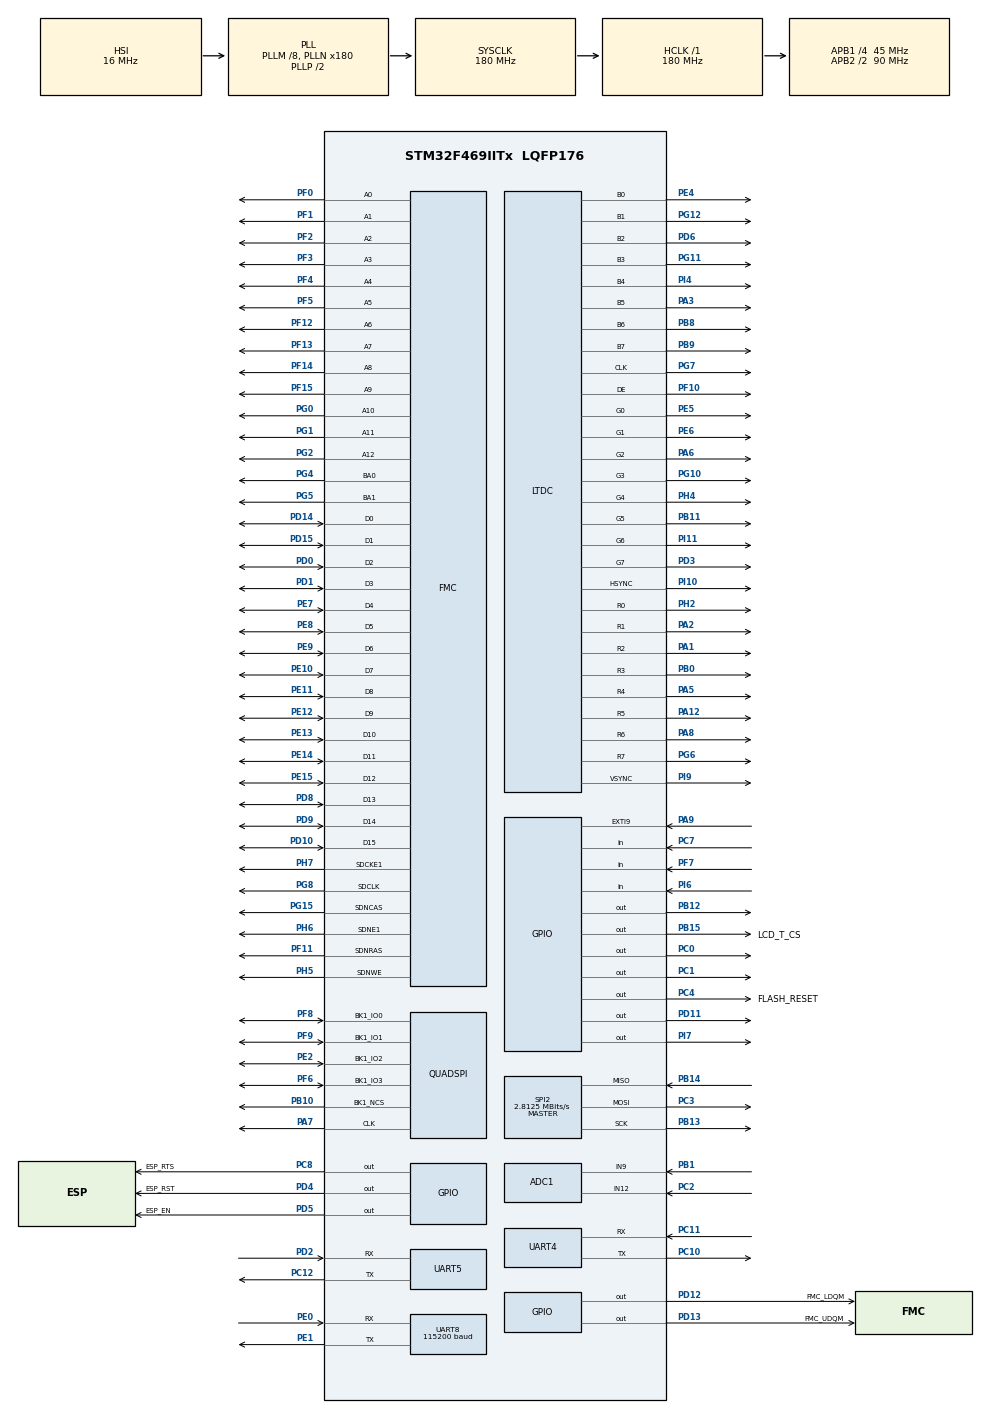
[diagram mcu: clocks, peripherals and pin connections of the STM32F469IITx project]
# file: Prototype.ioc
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ADC1.Channel-1\#ChannelRegularConversion=ADC_CHANNEL_VREFINT
ADC1.ContinuousConvMode=ENABLE
ADC1.DiscontinuousConvMode=DISABLE
ADC1.EnableAnalogWatchDog=false
ADC1.ExternalTrigConv=ADC_SOFTWARE_START
ADC1.InjNumberOfConversion=0
ADC1.NbrOfConversion=1
ADC1.NbrOfConversionFlag=1
ADC1.Rank-1\#ChannelRegularConversion=1
ADC1.SamplingTime-1\#ChannelRegularConversion=ADC_SAMPLETIME_480CYCLES
ADC1.ScanConvMode=ENABLE
ADC1.master=1
DMA2D.ColorMode=DMA2D_OUTPUT_RGB888
Dma.ADC1.0.Direction=DMA_PERIPH_TO_MEMORY
Dma.ADC1.0.FIFOMode=DMA_FIFOMODE_DISABLE
Dma.ADC1.0.Instance=DMA2_Stream0
Dma.ADC1.0.MemDataAlignment=DMA_MDATAALIGN_HALFWORD
Dma.ADC1.0.MemInc=DMA_MINC_ENABLE
Dma.ADC1.0.Mode=DMA_CIRCULAR
Dma.ADC1.0.PeriphDataAlignment=DMA_PDATAALIGN_HALFWORD
Dma.ADC1.0.PeriphInc=DMA_PINC_DISABLE
Dma.ADC1.0.Priority=DMA_PRIORITY_LOW
Dma.Request0=ADC1
FMC.CASLatency1=FMC_SDRAM_CAS_LATENCY_2
FMC.ExitSelfRefreshDelay1=7
FMC.LoadToActiveDelay1=2
FMC.RCDDelay1=3
FMC.RPDelay1=2
FMC.RPDelay2=2
FMC.RowCycleDelay1=6
FMC.RowCycleDelay2=6
FMC.SDClockPeriod1=FMC_SDRAM_CLOCK_PERIOD_2
FMC.SelfRefreshTime1=6
FMC.WriteRecoveryTime1=3
FREERTOS.Tasks01=defaultTask,24,4096,StartDefaultTask,Default,NULL,Dynamic,NULL,NULL
FREERTOS.configTOTAL_HEAP_SIZE=30000
FREERTOS.configUSE_NEWLIB_REENTRANT=1
LTDC.ActiveW=800
LTDC.Alpha0_L0=0
LTDC.Alpha0_L1=0
LTDC.Alpha_L0=255
LTDC.BlendingFactor1_L0=LTDC_BLENDING_FACTOR1_PAxCA
LTDC.BlendingFactor1_L1=LTDC_BLENDING_FACTOR1_PAxCA
LTDC.BlendingFactor2_L0=LTDC_BLENDING_FACTOR2_PAxCA
LTDC.BlendingFactor2_L1=LTDC_BLENDING_FACTOR2_PAxCA
LTDC.Blue_L0=0
LTDC.Blue_L1=255
LTDC.Green=0
LTDC.Green_L0=0
LTDC.Green_L1=255
LTDC.HBP=46
LTDC.HFP=210
LTDC.HSync=41
LTDC.ImageHeight_L0=480
LTDC.ImageWidth_L0=800
LTDC.ImageWidth_L1=800
LTDC.Layers=0
LTDC.PixelFormat_L0=LTDC_PIXEL_FORMAT_RGB888
LTDC.PixelFormat_L1=LTDC_PIXEL_FORMAT_RGB565
LTDC.Red=0
LTDC.Red_L0=0
LTDC.Red_L1=255
LTDC.VBP=23
LTDC.VFP=22
LTDC.VSync=20
LTDC.WindowX1_L0=800
LTDC.WindowX1_L1=800
LTDC.WindowY1_L0=480
LTDC.WindowY1_L1=480
Mcu.Family=STM32F4
Mcu.Name=STM32F469IITx
Mcu.Package=LQFP176
NVIC.DMA2D_IRQn=true\:5\:0\:false\:false\:true\:true\:true\:true\:true
NVIC.DMA2_Stream0_IRQn=true\:5\:0\:false\:false\:true\:true\:false\:true\:true
NVIC.LTDC_IRQn=true\:5\:0\:true\:false\:true\:true\:true\:true\:true
NVIC.PriorityGroup=NVIC_PRIORITYGROUP_4
NVIC.TIM6_DAC_IRQn=true\:15\:0\:true\:false\:true\:false\:false\:true\:true
NVIC.TimeBase=TIM6_DAC_IRQn
NVIC.TimeBaseIP=TIM6
PA0/WKUP.Mode=SYS_WakeUp0
PA0/WKUP.Signal=SYS_WKUP
PA1.Mode=RGB888
PA1.Signal=LTDC_R2
PA12.Mode=RGB888
PA12.Signal=LTDC_R5
PA13.Mode=JTAG_5_pins
PA13.Signal=SYS_JTMS-SWDIO
PA14.Mode=JTAG_5_pins
PA14.Signal=SYS_JTCK-SWCLK
PA15.Mode=JTAG_5_pins
PA15.Signal=SYS_JTDI
PA2.Mode=RGB888
PA2.Signal=LTDC_R1
PA3.Mode=RGB888
PA3.Signal=LTDC_B5
PA5.Mode=RGB888
PA5.Signal=LTDC_R4
PA6.Mode=RGB888
PA6.Signal=LTDC_G2
PA7.Mode=Single Bank 1
PA7.Signal=QUADSPI_CLK
PA8.Mode=RGB888
PA8.Signal=LTDC_R6
PA9.GPIO_ModeDefaultEXTI=GPIO_MODE_IT_FALLING
PA9.GPIO_PuPd=GPIO_PULLUP
PA9.Signal=GPXTI9
PB0.Mode=RGB888
PB0.Signal=LTDC_R3
PB1.Signal=ADCx_IN9
PB10.Mode=Single Bank 1
PB10.Signal=QUADSPI_BK1_NCS
PB11.Mode=RGB888
PB11.Signal=LTDC_G5
PB12.Signal=GPIO_Output
PB13.Mode=Full_Duplex_Master
PB13.Signal=SPI2_SCK
PB14.Mode=Full_Duplex_Master
PB14.Signal=SPI2_MISO
PB15.GPIO_Label=LCD_T_CS
PB15.Signal=GPIO_Output
PB3.Mode=JTAG_5_pins
PB3.Signal=SYS_JTDO-SWO
PB4.Mode=JTAG_5_pins
PB4.Signal=SYS_JTRST
PB8.Mode=RGB888
PB8.Signal=LTDC_B6
PB9.Mode=RGB888
PB9.Signal=LTDC_B7
PC0.Signal=GPIO_Output
PC1.Signal=GPIO_Output
PC10.Mode=Asynchronous
PC10.Signal=UART4_TX
PC11.Mode=Asynchronous
PC11.Signal=UART4_RX
PC12.Mode=Asynchronous
PC12.Signal=UART5_TX
PC2.Signal=ADCx_IN12
PC3.Mode=Full_Duplex_Master
PC3.Signal=SPI2_MOSI
PC4.GPIO_Label=FLASH_RESET
PC4.Signal=GPIO_Output
PC7.Signal=GPIO_Input
PC8.GPIO_Label=ESP_RTS
PC8.Signal=GPIO_Output
PD0.Signal=FMC_D2_DA2
PD1.Signal=FMC_D3_DA3
PD10.Signal=FMC_D15_DA15
PD11.Signal=GPIO_Output
PD12.GPIO_Label=FMC_LDQM
PD12.Signal=GPIO_Output
PD13.GPIO_Label=FMC_UDQM
PD13.Signal=GPIO_Output
PD14.Signal=FMC_D0_DA0
PD15.Signal=FMC_D1_DA1
PD2.Mode=Asynchronous
PD2.Signal=UART5_RX
PD3.Mode=RGB888
PD3.Signal=LTDC_G7
PD4.GPIO_Label=ESP_RST
PD4.Signal=GPIO_Output
PD5.GPIO_Label=ESP_EN
PD5.GPIO_ModeDefaultOutputPP=GPIO_MODE_OUTPUT_OD
PD5.GPIO_PuPd=GPIO_PULLUP
PD5.Signal=GPIO_Output
PD6.Mode=RGB888
PD6.Signal=LTDC_B2
PD8.Signal=FMC_D13_DA13
PD9.Signal=FMC_D14_DA14
PE0.Mode=Asynchronous
PE0.Signal=UART8_RX
PE1.Mode=Asynchronous
PE1.Signal=UART8_TX
PE10.Signal=FMC_D7_DA7
PE11.Signal=FMC_D8_DA8
PE12.Signal=FMC_D9_DA9
PE13.Signal=FMC_D10_DA10
PE14.Signal=FMC_D11_DA11
PE15.Signal=FMC_D12_DA12
PE2.Mode=Single Bank 1
PE2.Signal=QUADSPI_BK1_IO2
PE4.Mode=RGB888
PE4.Signal=LTDC_B0
PE5.Mode=RGB888
PE5.Signal=LTDC_G0
PE6.Mode=RGB888
PE6.Signal=LTDC_G1
PE7.Signal=FMC_D4_DA4
PE8.Signal=FMC_D5_DA5
PE9.Signal=FMC_D6_DA6
PF0.Signal=FMC_A0
PF1.Signal=FMC_A1
PF10.Mode=RGB888
PF10.Signal=LTDC_DE
PF11.Signal=FMC_SDNRAS
PF12.Signal=FMC_A6
PF13.Signal=FMC_A7
PF14.Signal=FMC_A8
PF15.Signal=FMC_A9
PF2.Signal=FMC_A2
PF3.Signal=FMC_A3
PF4.Signal=FMC_A4
PF5.Signal=FMC_A5
PF6.Mode=Single Bank 1
PF6.Signal=QUADSPI_BK1_IO3
PF7.Signal=GPIO_Input
PF8.Mode=Single Bank 1
PF8.Signal=QUADSPI_BK1_IO0
PF9.Mode=Single Bank 1
PF9.Signal=QUADSPI_BK1_IO1
PG0.Signal=FMC_A10
PG1.Signal=FMC_A11
PG10.Mode=RGB888
PG10.Signal=LTDC_G3
PG11.Mode=RGB888
PG11.Signal=LTDC_B3
PG12.Mode=RGB888
PG12.Signal=LTDC_B1
PG15.Signal=FMC_SDNCAS
PG2.Signal=FMC_A12
PG4.Signal=FMC_A14_BA0
PG5.Signal=FMC_A15_BA1
PG6.Mode=RGB888
PG6.Signal=LTDC_R7
PG7.Mode=RGB888
PG7.Signal=LTDC_CLK
PG8.Signal=FMC_SDCLK
PH2.Mode=RGB888
PH2.Signal=LTDC_R0
PH4.Mode=RGB888
PH4.Signal=LTDC_G4
PH5.Signal=FMC_SDNWE
PH6.Mode=SdramChipSelect2_1
PH6.Signal=FMC_SDNE1
PH7.Mode=SdramChipSelect2_1
PH7.Signal=FMC_SDCKE1
PI10.Mode=RGB888
PI10.Signal=LTDC_HSYNC
PI11.Mode=RGB888
PI11.Signal=LTDC_G6
PI4.Mode=RGB888
PI4.Signal=LTDC_B4
PI6.Signal=GPIO_Input
PI7.Signal=GPIO_Output
PI9.Mode=RGB888
PI9.Signal=LTDC_VSYNC
ProjectManager.HeapSize=0x200
ProjectManager.StackSize=0x400
ProjectManager.TargetToolchain=STM32CubeIDE
RCC.AHBFreq_Value=180000000
RCC.APB1CLKDivider=RCC_HCLK_DIV4
RCC.APB1Freq_Value=45000000
RCC.APB1TimFreq_Value=90000000
RCC.APB2CLKDivider=RCC_HCLK_DIV2
RCC.APB2Freq_Value=90000000
RCC.APB2TimFreq_Value=180000000
RCC.CortexFreq_Value=180000000
RCC.HCLKFreq_Value=180000000
RCC.HSE_VALUE=25000000
RCC.PLLM=8
RCC.PLLN=180
RCC.PLLSAIN=50
RCC.SYSCLKFreq_VALUE=180000000
RCC.SYSCLKSource=RCC_SYSCLKSOURCE_PLLCLK
RCC.USBFreq_Value=90000000
RCC.VCOOutputFreq_Value=360000000
SH.ADCx_IN12.0=ADC1_IN12,IN12
SH.ADCx_IN9.0=ADC1_IN9,IN9
SH.FMC_A0.0=FMC_A0,13b-sda1
SH.FMC_A1.0=FMC_A1,13b-sda1
SH.FMC_A10.0=FMC_A10,13b-sda1
SH.FMC_A11.0=FMC_A11,13b-sda1
SH.FMC_A12.0=FMC_A12,13b-sda1
SH.FMC_A14_BA0.0=FMC_BA0,FourSdramBanks1
SH.FMC_A15_BA1.0=FMC_BA1,FourSdramBanks1
SH.FMC_A2.0=FMC_A2,13b-sda1
SH.FMC_A3.0=FMC_A3,13b-sda1
SH.FMC_A4.0=FMC_A4,13b-sda1
SH.FMC_A5.0=FMC_A5,13b-sda1
SH.FMC_A6.0=FMC_A6,13b-sda1
SH.FMC_A7.0=FMC_A7,13b-sda1
SH.FMC_A8.0=FMC_A8,13b-sda1
SH.FMC_A9.0=FMC_A9,13b-sda1
SH.FMC_D0_DA0.0=FMC_D0,sd-16b-d1
SH.FMC_D10_DA10.0=FMC_D10,sd-16b-d1
SH.FMC_D11_DA11.0=FMC_D11,sd-16b-d1
SH.FMC_D12_DA12.0=FMC_D12,sd-16b-d1
SH.FMC_D13_DA13.0=FMC_D13,sd-16b-d1
SH.FMC_D14_DA14.0=FMC_D14,sd-16b-d1
SH.FMC_D15_DA15.0=FMC_D15,sd-16b-d1
SH.FMC_D1_DA1.0=FMC_D1,sd-16b-d1
SH.FMC_D2_DA2.0=FMC_D2,sd-16b-d1
SH.FMC_D3_DA3.0=FMC_D3,sd-16b-d1
SH.FMC_D4_DA4.0=FMC_D4,sd-16b-d1
SH.FMC_D5_DA5.0=FMC_D5,sd-16b-d1
SH.FMC_D6_DA6.0=FMC_D6,sd-16b-d1
SH.FMC_D7_DA7.0=FMC_D7,sd-16b-d1
SH.FMC_D8_DA8.0=FMC_D8,sd-16b-d1
SH.FMC_D9_DA9.0=FMC_D9,sd-16b-d1
SH.FMC_SDCLK.0=FMC_SDCLK,13b-sda1
SH.FMC_SDNCAS.0=FMC_SDNCAS,13b-sda1
SH.FMC_SDNRAS.0=FMC_SDNRAS,13b-sda1
SH.FMC_SDNWE.0=FMC_SDNWE,13b-sda1
SPI2.BaudRatePrescaler=SPI_BAUDRATEPRESCALER_16
SPI2.CalculateBaudRate=2.8125 MBits/s
SPI2.Direction=SPI_DIRECTION_2LINES
SPI2.Mode=SPI_MODE_MASTER
SPI2.VirtualType=VM_MASTER
STMicroelectronics.X-CUBE-TOUCHGFX.4.25.0.ApplicationCcGraphicsJjApplication=TouchGFXOoGenerator
STMicroelectronics.X-CUBE-TOUCHGFX.4.25.0.tgfx_address1=0xD0000000
STMicroelectronics.X-CUBE-TOUCHGFX.4.25.0.tgfx_custom_height=480
STMicroelectronics.X-CUBE-TOUCHGFX.4.25.0.tgfx_datareader_mem_base_address=0xD0000000
STMicroelectronics.X-CUBE-TOUCHGFX.4.25.0.tgfx_display_interface=disp_ltdc
STMicroelectronics.X-CUBE-TOUCHGFX.4.25.0.tgfx_framebuffer_stride=Disabled
STMicroelectronics.X-CUBE-TOUCHGFX.4.25.0.tgfx_hardware_accelerator=dma_2d
STMicroelectronics.X-CUBE-TOUCHGFX.4.25.0.tgfx_location=By Address
STMicroelectronics.X-CUBE-TOUCHGFX.4.25.0.tgfx_vsync=vsync_ltdc
STMicroelectronics.X-CUBE-TOUCHGFX.4.25.0_IsPackSelfContextualization=true
UART4.VirtualMode=Asynchronous
UART5.VirtualMode=Asynchronous
UART8.BaudRate=115200
UART8.VirtualMode=Asynchronous
VP_ADC1_Vref_Input.Mode=IN-Vrefint
VP_CRC_VS_CRC.Mode=CRC_Activate
VP_DMA2D_VS_DMA2D.Mode=DMA2D_Activate
VP_FREERTOS_VS_CMSIS_V2.Mode=CMSIS_V2
VP_STMicroelectronics.X-CUBE-TOUCHGFX_VS_GraphicsJjApplication_4.25.0.Mode=GraphicsJjApplication
VP_SYS_VS_tim6.Mode=TIM6
board=custom

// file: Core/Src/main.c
/* USER CODE BEGIN Header */
/**
  ******************************************************************************
  * @file           : main.c
  * @brief          : Main program body
  ******************************************************************************
  * @attention
  *
  * Copyright (c) 2025 STMicroelectronics.
  * All rights reserved.
  *
  * This software is licensed under terms that can be found in the LICENSE file
  * in the root directory of this software component.
  * If no LICENSE file comes with this software, it is provided AS-IS.
  *
  ******************************************************************************
  */
/* USER CODE END Header */
#include "main.h"
#include "cmsis_os.h"
#include "app_touchgfx.h"

/* USER CODE BEGIN Includes */
#include<stdlib.h>
#include<stdio.h>
#include<string.h>
#include<stdbool.h>
#include <stdint.h>
#include <serial_printing.h>
#include "GUI.h"
#include "types.h"
#include "touch.h"
#include "control.h"

// Initialize the framebuffer to a specific color, e.g., 0xFFFF (white in RGB565)

/*static const uint8_t framebuffer[FRAMEBUFFER_SIZE] = {
    [0 ... FRAMEBUFFER_SIZE - 1] = color_index  // GNU C extension to initialize all elements
};*/ /*780 x 400*/
uint32_t adcs[2] = {0};
/* USER CODE END Includes */

/* USER CODE BEGIN PD */
volatile uint8_t uart8_tx_complete = 0;
/* USER CODE END PD */

ADC_HandleTypeDef hadc1;
DMA_HandleTypeDef hdma_adc1;

CRC_HandleTypeDef hcrc;

DMA2D_HandleTypeDef hdma2d;

LTDC_HandleTypeDef hltdc;

QSPI_HandleTypeDef hqspi;

SPI_HandleTypeDef hspi2;

UART_HandleTypeDef huart4;
UART_HandleTypeDef huart5;
UART_HandleTypeDef huart8;

SDRAM_HandleTypeDef hsdram1;

/* Definitions for defaultTask */
osThreadId_t defaultTaskHandle;
const osThreadAttr_t defaultTask_attributes = {
  .name = "defaultTask",
  .stack_size = 4096 * 4,
  .priority = (osPriority_t) osPriorityNormal,
};
/* USER CODE BEGIN PV */
__IO uint16_t uhADCxConvertedValue = 0;
uint8_t         ubAnalogWatchdogStatus = RESET;

ADC_ChannelConfTypeDef sConfig = {0};
GPIO_InitTypeDef GPIO_InitStruct = {0};

/* USER CODE END PV */

void SystemClock_Config(void);
static void MX_GPIO_Init(void);
static void MX_DMA_Init(void);
static void MX_LTDC_Init(void);
static void MX_FMC_Init(void);
static void MX_ADC1_Init(void);
static void MX_QUADSPI_Init(void);
static void MX_SPI2_Init(void);
static void MX_UART4_Init(void);
static void MX_UART8_Init(void);
static void MX_UART5_Init(void);
static void MX_CRC_Init(void);
static void MX_DMA2D_Init(void);
void StartDefaultTask(void *argument);

/* USER CODE BEGIN PFP */
void RESTORE_ADC();
/* USER CODE END PFP */

/* USER CODE BEGIN 0 */

char rxBuffer[1024];
uint8_t flag = 0x00;
char uartBuffer[1024] = {};
uint16_t *BUFFER_LAYER_1;
uint16_t *BUFFER_LAYER_2;
uint32_t ADC_THREAD_CONTROL_BIT;
uint32_t UART_THREAD_CONTROL_BIT;
uint32_t LCD_THREAD_CONTROL_BIT;

uint32_t MAIN_THREAD_ADC_CONTROL_BIT;
uint32_t MAIN_THREAD_UART_CONTROL_BIT;
uint32_t MAIN_THREAD_LCD_CONTROL_BIT;

DATA_HOLDER mainDataHolder;
DATA_HOLDER lcdDataHolder;

CMD cmd = {
		.origin = {0},
		.protocol = {0},
		.command = {0},
		.args = {0},
		.cmd_all = {0},
		.cmd_all_tmp = {0},
		.cmd_flag = 0x00,
		.status_busy = false
};

Button button = {
		  .c = {0},
		  .data = 25,
		  .n = 0,
		  .rst = false,
		  .set = false,
		  .temp_set = 0,
		  .valid = false,
		  .value = 0
};
Pressed pressed = {
		  .X_ = 0,
		  .Y_=0
};
char msg2[100];
/* USER CODE END 0 */

int main(void)
{

  /* USER CODE BEGIN 1 */
	strcpy(mainDataHolder.callingWaterTemp, "calling");
	strcpy(mainDataHolder.hotWaterTemp, "hot");
	strcpy(mainDataHolder.motor_position, "motor");
	strcpy(mainDataHolder.showerWaterTemp, "shower");

	lcdDataHolder.setTemp = 25;
	//uint16_t *BUFFER_LAYER_1 = (uint16_t *)BUFFER_LAYER_1_ADDRESS;
	//uint16_t *BUFFER_LAYER_2 = (uint16_t *)BUFFER_LAYER_2_ADDRESS;

    //HAL_SDRAM_Write_16b(&hsdram1, (uint32_t *)BUFFER_LAYER_1, (uint16_t *)RGB565_Dark_sky_blue, FRAMEBUFFER_WIDTH * FRAMEBUFFER_HEIGHT);

  /* USER CODE END 1 */

  /* MCU Configuration--------------------------------------------------------*/

  /* Reset of all peripherals, Initializes the Flash interface and the Systick. */
  HAL_Init();

  /* Configure the system clock */
  SystemClock_Config();

  /* Initialize all configured peripherals */
  MX_GPIO_Init();
  MX_DMA_Init();
  MX_LTDC_Init();
  MX_FMC_Init();
  MX_ADC1_Init();
  MX_QUADSPI_Init();
  MX_SPI2_Init();
  MX_UART4_Init();
  MX_UART8_Init();
  MX_UART5_Init();
  MX_CRC_Init();
  MX_DMA2D_Init();
  MX_TouchGFX_Init();
  /* Call PreOsInit function */
  MX_TouchGFX_PreOSInit();
  /* USER CODE BEGIN 2 */

  /* Infinite loop */
	// Allocate buffer

	//  int y_ = 0;

	/*  uint16_t yellow_rgb565 = 0x0f0f;
	  for (int y = 0; y < FRAMEBUFFER_HEIGHT; y++) {
	          for (int x = 0; x < FRAMEBUFFER_WIDTH; x++) {
	        	  uint32_t index = y * FRAMEBUFFER_WIDTH + x; // 1D index
	        	  uint32_t address = (uint32_t)BUFFER_LAYER_1_ADDRESS + index * BYTES_PER_PIXEL; // SDRAM address
	              HAL_SDRAM_Write_16b(&hsdram1, (uint32_t *)address, &yellow_rgb565, 1);
	              address += BYTES_PER_PIXEL; // Increment by 2 bytes for each pixel
	          }
	      }*/
	  HAL_Delay(1000);

	//LCD_Fill(BUFFER_LAYER_1_ADDRESS, 0, 0,FRAMEBUFFER_WIDTH,FRAMEBUFFER_HEIGHT,RGB565_Celtic_blue);
	ESP_RST_GPIO_Port->BSRR = 1U << (4+16);
	ESP_EN_GPIO_Port->BSRR = 1U << (5+16);
	HAL_Delay(1000);
	ESP_RST_GPIO_Port->BSRR = 1U << (4);
	ESP_EN_GPIO_Port->BSRR = 1U << 5;

	//sprintf(msg2, "JUST GOT HERE 7\n");
	//HAL_UART_Transmit(&huart8, (uint8_t *)msg2, strlen(msg2), 1000);

	HAL_Delay(1000);
	ESP_RTS_GPIO_Port->BSRR = 1U << (8+16);
	//ESP_RTS_GPIO_Port->BSRR = 1U << (8);
	GPIOC->BSRR = 1U << 2; // YD
	//char msg1[100] = "RUN 2 200";
//	MX_TouchGFX_Init();
  /* USER CODE END 2 */

  /* Init scheduler */
  osKernelInitialize();

  /* Create the thread(s) */
  /* creation of defaultTask */
  defaultTaskHandle = osThreadNew(StartDefaultTask, NULL, &defaultTask_attributes);

  /* Start scheduler */
  osKernelStart();

  /* We should never get here as control is now taken by the scheduler */

  /* Infinite loop */
  /* USER CODE BEGIN WHILE */
	//memset(adcReadings, 0, sizeof(adcReadings));
    //HAL_ADC_Start_DMA(&hadc1, (uint32_t *)adcReadings, 1000);
  while (1)
  {
    /* USER CODE END WHILE */

    /* USER CODE BEGIN 3 */
	  //HAL_SDRAM_Read_8b(&hsdram1, (uint32_t *)BUFFER_LAYER_1, (uint8_t *)myReadData, 4);
	// Reconfigure ADC to use the correct input channel (e.g., ADC_CHANNEL_9 on PB1
	//printf_(buffer2, myReadData);
  }
  /* USER CODE END 3 */
}

void SystemClock_Config(void)
{
  RCC_OscInitTypeDef RCC_OscInitStruct = {0};
  RCC_ClkInitTypeDef RCC_ClkInitStruct = {0};

  /** Configure the main internal regulator output voltage
  */
  __HAL_RCC_PWR_CLK_ENABLE();
  __HAL_PWR_VOLTAGESCALING_CONFIG(PWR_REGULATOR_VOLTAGE_SCALE1);

  /** Initializes the RCC Oscillators according to the specified parameters
  * in the RCC_OscInitTypeDef structure.
  */
  RCC_OscInitStruct.OscillatorType = RCC_OSCILLATORTYPE_HSI;
  RCC_OscInitStruct.HSIState = RCC_HSI_ON;
  RCC_OscInitStruct.HSICalibrationValue = RCC_HSICALIBRATION_DEFAULT;
  RCC_OscInitStruct.PLL.PLLState = RCC_PLL_ON;
  RCC_OscInitStruct.PLL.PLLSource = RCC_PLLSOURCE_HSI;
  RCC_OscInitStruct.PLL.PLLM = 8;
  RCC_OscInitStruct.PLL.PLLN = 180;
  RCC_OscInitStruct.PLL.PLLP = RCC_PLLP_DIV2;
  RCC_OscInitStruct.PLL.PLLQ = 4;
  RCC_OscInitStruct.PLL.PLLR = 2;
  if (HAL_RCC_OscConfig(&RCC_OscInitStruct) != HAL_OK)
  {
    Error_Handler();
  }

  /** Activate the Over-Drive mode
  */
  if (HAL_PWREx_EnableOverDrive() != HAL_OK)
  {
    Error_Handler();
  }

  /** Initializes the CPU, AHB and APB buses clocks
  */
  RCC_ClkInitStruct.ClockType = RCC_CLOCKTYPE_HCLK|RCC_CLOCKTYPE_SYSCLK
                              |RCC_CLOCKTYPE_PCLK1|RCC_CLOCKTYPE_PCLK2;
  RCC_ClkInitStruct.SYSCLKSource = RCC_SYSCLKSOURCE_PLLCLK;
  RCC_ClkInitStruct.AHBCLKDivider = RCC_SYSCLK_DIV1;
  RCC_ClkInitStruct.APB1CLKDivider = RCC_HCLK_DIV4;
  RCC_ClkInitStruct.APB2CLKDivider = RCC_HCLK_DIV2;

  if (HAL_RCC_ClockConfig(&RCC_ClkInitStruct, FLASH_LATENCY_5) != HAL_OK)
  {
    Error_Handler();
  }
}

static void MX_ADC1_Init(void)
{

  ADC_ChannelConfTypeDef sConfig = {0};

  /** Configure the global features of the ADC (Clock, Resolution, Data Alignment and number of conversion)
  */
  hadc1.Instance = ADC1;
  hadc1.Init.ClockPrescaler = ADC_CLOCK_SYNC_PCLK_DIV4;
  hadc1.Init.Resolution = ADC_RESOLUTION_12B;
  hadc1.Init.ScanConvMode = ENABLE;
  hadc1.Init.ContinuousConvMode = ENABLE;
  hadc1.Init.DiscontinuousConvMode = DISABLE;
  hadc1.Init.ExternalTrigConvEdge = ADC_EXTERNALTRIGCONVEDGE_NONE;
  hadc1.Init.ExternalTrigConv = ADC_SOFTWARE_START;
  hadc1.Init.DataAlign = ADC_DATAALIGN_RIGHT;
  hadc1.Init.NbrOfConversion = 1;
  hadc1.Init.DMAContinuousRequests = DISABLE;
  hadc1.Init.EOCSelection = ADC_EOC_SINGLE_CONV;
  if (HAL_ADC_Init(&hadc1) != HAL_OK)
  {
    Error_Handler();
  }

  /** Configure for the selected ADC regular channel its corresponding rank in the sequencer and its sample time.
  */
  sConfig.Channel = ADC_CHANNEL_VREFINT;
  sConfig.Rank = 1;
  sConfig.SamplingTime = ADC_SAMPLETIME_480CYCLES;
  if (HAL_ADC_ConfigChannel(&hadc1, &sConfig) != HAL_OK)
  {
    Error_Handler();
  }

}

static void MX_CRC_Init(void)
{

  hcrc.Instance = CRC;
  if (HAL_CRC_Init(&hcrc) != HAL_OK)
  {
    Error_Handler();
  }

}

static void MX_DMA2D_Init(void)
{

  hdma2d.Instance = DMA2D;
  hdma2d.Init.Mode = DMA2D_M2M;
  hdma2d.Init.ColorMode = DMA2D_OUTPUT_RGB888;
  hdma2d.Init.OutputOffset = 0;
  hdma2d.LayerCfg[1].InputOffset = 0;
  hdma2d.LayerCfg[1].InputColorMode = DMA2D_INPUT_RGB888;
  hdma2d.LayerCfg[1].AlphaMode = DMA2D_NO_MODIF_ALPHA;
  hdma2d.LayerCfg[1].InputAlpha = 0;
  if (HAL_DMA2D_Init(&hdma2d) != HAL_OK)
  {
    Error_Handler();
  }
  if (HAL_DMA2D_ConfigLayer(&hdma2d, 1) != HAL_OK)
  {
    Error_Handler();
  }

}

static void MX_LTDC_Init(void)
{

  /* USER CODE BEGIN LTDC_Init 0 */
	GPIOB->BSRR = (1U << 12);

  /* USER CODE END LTDC_Init 0 */

  LTDC_LayerCfgTypeDef pLayerCfg = {0};

  hltdc.Instance = LTDC;
  hltdc.Init.HSPolarity = LTDC_HSPOLARITY_AL;
  hltdc.Init.VSPolarity = LTDC_VSPOLARITY_AL;
  hltdc.Init.DEPolarity = LTDC_DEPOLARITY_AL;
  hltdc.Init.PCPolarity = LTDC_PCPOLARITY_IPC;
  hltdc.Init.HorizontalSync = 40;
  hltdc.Init.VerticalSync = 19;
  hltdc.Init.AccumulatedHBP = 86;
  hltdc.Init.AccumulatedVBP = 42;
  hltdc.Init.AccumulatedActiveW = 886;
  hltdc.Init.AccumulatedActiveH = 522;
  hltdc.Init.TotalWidth = 1096;
  hltdc.Init.TotalHeigh = 544;
  hltdc.Init.Backcolor.Blue = 0;
  hltdc.Init.Backcolor.Green = 0;
  hltdc.Init.Backcolor.Red = 0;
  if (HAL_LTDC_Init(&hltdc) != HAL_OK)
  {
    Error_Handler();
  }
  pLayerCfg.WindowX0 = 0;
  pLayerCfg.WindowX1 = 800;
  pLayerCfg.WindowY0 = 0;
  pLayerCfg.WindowY1 = 480;
  pLayerCfg.PixelFormat = LTDC_PIXEL_FORMAT_RGB888;
  pLayerCfg.Alpha = 255;
  pLayerCfg.Alpha0 = 0;
  pLayerCfg.BlendingFactor1 = LTDC_BLENDING_FACTOR1_PAxCA;
  pLayerCfg.BlendingFactor2 = LTDC_BLENDING_FACTOR2_PAxCA;
  pLayerCfg.FBStartAdress = ((uint32_t)0xD0000000);
  pLayerCfg.ImageWidth = 800;
  pLayerCfg.ImageHeight = 480;
  pLayerCfg.Backcolor.Blue = 0;
  pLayerCfg.Backcolor.Green = 0;
  pLayerCfg.Backcolor.Red = 0;
  if (HAL_LTDC_ConfigLayer(&hltdc, &pLayerCfg, 0) != HAL_OK)
  {
    Error_Handler();
  }

}

static void MX_QUADSPI_Init(void)
{

  /* QUADSPI parameter configuration*/
  hqspi.Instance = QUADSPI;
  hqspi.Init.ClockPrescaler = 255;
  hqspi.Init.FifoThreshold = 1;
  hqspi.Init.SampleShifting = QSPI_SAMPLE_SHIFTING_NONE;
  hqspi.Init.FlashSize = 1;
  hqspi.Init.ChipSelectHighTime = QSPI_CS_HIGH_TIME_1_CYCLE;
  hqspi.Init.ClockMode = QSPI_CLOCK_MODE_0;
  hqspi.Init.FlashID = QSPI_FLASH_ID_1;
  hqspi.Init.DualFlash = QSPI_DUALFLASH_DISABLE;
  if (HAL_QSPI_Init(&hqspi) != HAL_OK)
  {
    Error_Handler();
  }

}

static void MX_SPI2_Init(void)
{

  /* SPI2 parameter configuration*/
  hspi2.Instance = SPI2;
  hspi2.Init.Mode = SPI_MODE_MASTER;
  hspi2.Init.Direction = SPI_DIRECTION_2LINES;
  hspi2.Init.DataSize = SPI_DATASIZE_8BIT;
  hspi2.Init.CLKPolarity = SPI_POLARITY_LOW;
  hspi2.Init.CLKPhase = SPI_PHASE_1EDGE;
  hspi2.Init.NSS = SPI_NSS_SOFT;
  hspi2.Init.BaudRatePrescaler = SPI_BAUDRATEPRESCALER_16;
  hspi2.Init.FirstBit = SPI_FIRSTBIT_MSB;
  hspi2.Init.TIMode = SPI_TIMODE_DISABLE;
  hspi2.Init.CRCCalculation = SPI_CRCCALCULATION_DISABLE;
  hspi2.Init.CRCPolynomial = 10;
  if (HAL_SPI_Init(&hspi2) != HAL_OK)
  {
    Error_Handler();
  }

}

static void MX_UART4_Init(void)
{

  huart4.Instance = UART4;
  huart4.Init.BaudRate = 115200;
  huart4.Init.WordLength = UART_WORDLENGTH_8B;
  huart4.Init.StopBits = UART_STOPBITS_1;
  huart4.Init.Parity = UART_PARITY_NONE;
  huart4.Init.Mode = UART_MODE_TX_RX;
  huart4.Init.HwFlowCtl = UART_HWCONTROL_NONE;
  huart4.Init.OverSampling = UART_OVERSAMPLING_16;
  if (HAL_UART_Init(&huart4) != HAL_OK)
  {
    Error_Handler();
  }

}

static void MX_UART5_Init(void)
{

  huart5.Instance = UART5;
  huart5.Init.BaudRate = 115200;
  huart5.Init.WordLength = UART_WORDLENGTH_8B;
  huart5.Init.StopBits = UART_STOPBITS_1;
  huart5.Init.Parity = UART_PARITY_NONE;
  huart5.Init.Mode = UART_MODE_TX_RX;
  huart5.Init.HwFlowCtl = UART_HWCONTROL_NONE;
  huart5.Init.OverSampling = UART_OVERSAMPLING_16;
  if (HAL_UART_Init(&huart5) != HAL_OK)
  {
    Error_Handler();
  }

}

static void MX_UART8_Init(void)
{

  huart8.Instance = UART8;
  huart8.Init.BaudRate = 115200;
  huart8.Init.WordLength = UART_WORDLENGTH_8B;
  huart8.Init.StopBits = UART_STOPBITS_1;
  huart8.Init.Parity = UART_PARITY_NONE;
  huart8.Init.Mode = UART_MODE_TX_RX;
  huart8.Init.HwFlowCtl = UART_HWCONTROL_NONE;
  huart8.Init.OverSampling = UART_OVERSAMPLING_16;
  if (HAL_UART_Init(&huart8) != HAL_OK)
  {
    Error_Handler();
  }

}

static void MX_DMA_Init(void)
{

  /* DMA controller clock enable */
  __HAL_RCC_DMA2_CLK_ENABLE();

  /* DMA interrupt init */
  /* DMA2_Stream0_IRQn interrupt configuration */
  HAL_NVIC_SetPriority(DMA2_Stream0_IRQn, 5, 0);
  HAL_NVIC_EnableIRQ(DMA2_Stream0_IRQn);

}

/* FMC initialization function */
static void MX_FMC_Init(void)
{

  FMC_SDRAM_TimingTypeDef SdramTiming = {0};

  /** Perform the SDRAM1 memory initialization sequence
  */
  hsdram1.Instance = FMC_SDRAM_DEVICE;
  /* hsdram1.Init */
  hsdram1.Init.SDBank = FMC_SDRAM_BANK2;
  hsdram1.Init.ColumnBitsNumber = FMC_SDRAM_COLUMN_BITS_NUM_8;
  hsdram1.Init.RowBitsNumber = FMC_SDRAM_ROW_BITS_NUM_13;
  hsdram1.Init.MemoryDataWidth = FMC_SDRAM_MEM_BUS_WIDTH_16;
  hsdram1.Init.InternalBankNumber = FMC_SDRAM_INTERN_BANKS_NUM_4;
  hsdram1.Init.CASLatency = FMC_SDRAM_CAS_LATENCY_2;
  hsdram1.Init.WriteProtection = FMC_SDRAM_WRITE_PROTECTION_DISABLE;
  hsdram1.Init.SDClockPeriod = FMC_SDRAM_CLOCK_PERIOD_2;
  hsdram1.Init.ReadBurst = FMC_SDRAM_RBURST_DISABLE;
  hsdram1.Init.ReadPipeDelay = FMC_SDRAM_RPIPE_DELAY_0;
  /* SdramTiming */
  SdramTiming.LoadToActiveDelay = 2;
  SdramTiming.ExitSelfRefreshDelay = 7;
  SdramTiming.SelfRefreshTime = 6;
  SdramTiming.RowCycleDelay = 6;
  SdramTiming.WriteRecoveryTime = 3;
  SdramTiming.RPDelay = 2;
  SdramTiming.RCDDelay = 3;

  if (HAL_SDRAM_Init(&hsdram1, &SdramTiming) != HAL_OK)
  {
    Error_Handler( );
  }

  /* USER CODE BEGIN FMC_Init 2 */
  FMC_SDRAM_CommandTypeDef Command;
   /* Step 1 and Step 2 already done in HAL_SDRAM_Init() */
   /* Step 3: Configure a clock configuration enable command */
    Command.CommandMode            = FMC_SDRAM_CMD_CLK_ENABLE;
    Command.CommandTarget          = FMC_SDRAM_CMD_TARGET_BANK2; // Corrected
    Command.AutoRefreshNumber      = 1;
    Command.ModeRegisterDefinition = 0;
    HAL_SDRAM_SendCommand(&hsdram1, &Command, 0xfff);
    HAL_Delay(1); /* Step 4: Insert 100 us minimum delay - Min HAL Delay is 1ms */
    /* Step 5: Configure a PALL (precharge all) command */
    Command.CommandMode            = FMC_SDRAM_CMD_PALL; /* Set MODE bits to "010" */
    HAL_SDRAM_SendCommand(&hsdram1, &Command, 0xfff);
    /* Step 6: Configure an Auto Refresh command */
    Command.CommandMode            = FMC_SDRAM_CMD_AUTOREFRESH_MODE; /* Set MODE bits to "011" */
    Command.AutoRefreshNumber      = 2;
    HAL_SDRAM_SendCommand(&hsdram1, &Command, 0xfff);
    /* Step 7: Program the external memory mode register */
    Command.CommandMode            = FMC_SDRAM_CMD_LOAD_MODE;/*set the MODE bits to "100" */
    Command.ModeRegisterDefinition =  (uint32_t)0 | 0<<3 | 2<<4 | 0<<7 | 1<<9;
    HAL_SDRAM_SendCommand(&hsdram1, &Command, 0xfff);
    /* Step 8: Set the refresh rate counter - refer to section SDRAM refresh timer register in RM0455 */
    /* Set the device refresh rate
     * COUNT = [(SDRAM self refresh time / number of row) x  SDRAM CLK] – 20
             = [(64ms/4096) * 100MHz] - 20 = 1562.5 - 20 ~ 1542 */
    HAL_SDRAM_ProgramRefreshRate(&hsdram1, 1404);
  /* USER CODE END FMC_Init 2 */
}

static void MX_GPIO_Init(void)
{
  GPIO_InitTypeDef GPIO_InitStruct = {0};

  /* GPIO Ports Clock Enable */
  __HAL_RCC_GPIOE_CLK_ENABLE();
  __HAL_RCC_GPIOI_CLK_ENABLE();
  __HAL_RCC_GPIOF_CLK_ENABLE();
  __HAL_RCC_GPIOC_CLK_ENABLE();
  __HAL_RCC_GPIOA_CLK_ENABLE();
  __HAL_RCC_GPIOH_CLK_ENABLE();
  __HAL_RCC_GPIOB_CLK_ENABLE();
  __HAL_RCC_GPIOG_CLK_ENABLE();
  __HAL_RCC_GPIOD_CLK_ENABLE();

  /*Configure GPIO pin Output Level */
  HAL_GPIO_WritePin(GPIOC, GPIO_PIN_0|GPIO_PIN_1|FLASH_RESET_Pin|ESP_RTS_Pin, GPIO_PIN_RESET);

  /*Configure GPIO pin Output Level */
  HAL_GPIO_WritePin(GPIOB, GPIO_PIN_12|LCD_T_CS_Pin, GPIO_PIN_RESET);

  /*Configure GPIO pin Output Level */
  HAL_GPIO_WritePin(GPIOD, GPIO_PIN_11|FMC_LDQM_Pin|FMC_UDQM_Pin|ESP_RST_Pin
                          |ESP_EN_Pin, GPIO_PIN_RESET);

  /*Configure GPIO pin Output Level */
  HAL_GPIO_WritePin(GPIOI, GPIO_PIN_7, GPIO_PIN_RESET);

  /*Configure GPIO pin : PF7 */
  GPIO_InitStruct.Pin = GPIO_PIN_7;
  GPIO_InitStruct.Mode = GPIO_MODE_INPUT;
  GPIO_InitStruct.Pull = GPIO_NOPULL;
  HAL_GPIO_Init(GPIOF, &GPIO_InitStruct);

  /*Configure GPIO pins : PC0 PC1 FLASH_RESET_Pin ESP_RTS_Pin */
  GPIO_InitStruct.Pin = GPIO_PIN_0|GPIO_PIN_1|FLASH_RESET_Pin|ESP_RTS_Pin;
  GPIO_InitStruct.Mode = GPIO_MODE_OUTPUT_PP;
  GPIO_InitStruct.Pull = GPIO_NOPULL;
  GPIO_InitStruct.Speed = GPIO_SPEED_FREQ_LOW;
  HAL_GPIO_Init(GPIOC, &GPIO_InitStruct);

  /*Configure GPIO pins : PB12 LCD_T_CS_Pin */
  GPIO_InitStruct.Pin = GPIO_PIN_12|LCD_T_CS_Pin;
  GPIO_InitStruct.Mode = GPIO_MODE_OUTPUT_PP;
  GPIO_InitStruct.Pull = GPIO_NOPULL;
  GPIO_InitStruct.Speed = GPIO_SPEED_FREQ_LOW;
  HAL_GPIO_Init(GPIOB, &GPIO_InitStruct);

  /*Configure GPIO pins : PD11 FMC_LDQM_Pin FMC_UDQM_Pin ESP_RST_Pin */
  GPIO_InitStruct.Pin = GPIO_PIN_11|FMC_LDQM_Pin|FMC_UDQM_Pin|ESP_RST_Pin;
  GPIO_InitStruct.Mode = GPIO_MODE_OUTPUT_PP;
  GPIO_InitStruct.Pull = GPIO_NOPULL;
  GPIO_InitStruct.Speed = GPIO_SPEED_FREQ_LOW;
  HAL_GPIO_Init(GPIOD, &GPIO_InitStruct);

  /*Configure GPIO pin : PC7 */
  GPIO_InitStruct.Pin = GPIO_PIN_7;
  GPIO_InitStruct.Mode = GPIO_MODE_INPUT;
  GPIO_InitStruct.Pull = GPIO_NOPULL;
  HAL_GPIO_Init(GPIOC, &GPIO_InitStruct);

  /*Configure GPIO pin : PA9 */
  GPIO_InitStruct.Pin = GPIO_PIN_9;
  GPIO_InitStruct.Mode = GPIO_MODE_IT_FALLING;
  GPIO_InitStruct.Pull = GPIO_PULLUP;
  HAL_GPIO_Init(GPIOA, &GPIO_InitStruct);

  /*Configure GPIO pin : ESP_EN_Pin */
  GPIO_InitStruct.Pin = ESP_EN_Pin;
  GPIO_InitStruct.Mode = GPIO_MODE_OUTPUT_OD;
  GPIO_InitStruct.Pull = GPIO_PULLUP;
  GPIO_InitStruct.Speed = GPIO_SPEED_FREQ_LOW;
  HAL_GPIO_Init(ESP_EN_GPIO_Port, &GPIO_InitStruct);

  /*Configure GPIO pin : PI6 */
  GPIO_InitStruct.Pin = GPIO_PIN_6;
  GPIO_InitStruct.Mode = GPIO_MODE_INPUT;
  GPIO_InitStruct.Pull = GPIO_NOPULL;
  HAL_GPIO_Init(GPIOI, &GPIO_InitStruct);

  /*Configure GPIO pin : PI7 */
  GPIO_InitStruct.Pin = GPIO_PIN_7;
  GPIO_InitStruct.Mode = GPIO_MODE_OUTPUT_PP;
  GPIO_InitStruct.Pull = GPIO_NOPULL;
  GPIO_InitStruct.Speed = GPIO_SPEED_FREQ_LOW;
  HAL_GPIO_Init(GPIOI, &GPIO_InitStruct);

}

/* USER CODE BEGIN 4 */

void RESTORE_ADC(){
	ADC_ChannelConfTypeDef sConfig = {0};
	GPIO_InitTypeDef GPIO_InitStruct = {0};

	GPIO_InitStruct.Pin = GPIO_PIN_2;
	GPIO_InitStruct.Mode = GPIO_MODE_OUTPUT_PP;
	HAL_GPIO_Init(GPIOC, &GPIO_InitStruct);
	HAL_GPIO_WritePin(GPIOC, GPIO_PIN_2, GPIO_PIN_SET);

	GPIO_InitStruct.Pin = GPIO_PIN_0;
	HAL_GPIO_Init(GPIOC, &GPIO_InitStruct);
	HAL_GPIO_WritePin(GPIOC, GPIO_PIN_0, GPIO_PIN_RESET);

	GPIO_InitStruct.Pin = GPIO_PIN_1;
	GPIO_InitStruct.Mode = GPIO_MODE_ANALOG;
	HAL_GPIO_Init(GPIOC, &GPIO_InitStruct);

	GPIO_InitStruct.Pin = GPIO_PIN_1;
	HAL_GPIO_Init(GPIOB, &GPIO_InitStruct);

	//osDelay(10);

	sConfig.Channel = ADC_CHANNEL_9;
	sConfig.Rank = 1;
	sConfig.SamplingTime = ADC_SAMPLETIME_480CYCLES;
	HAL_ADC_ConfigChannel(&hadc1, &sConfig);
}

// DMA Transfer Complete Callback
void HAL_UART_TxCpltCallback(UART_HandleTypeDef *huart)
{
  if (huart->Instance == UART8) // Check if it's the UART8 transfer
  {
    uart8_tx_complete = 1;
  }
}
/* USER CODE END 4 */

void StartDefaultTask(void *argument)
{
  /* USER CODE BEGIN 5 */
  /* Infinite loop */
  for(;;)
  {
	MX_TouchGFX_Process();
    osDelay(1);
  }
  /* USER CODE END 5 */
}

void HAL_TIM_PeriodElapsedCallback(TIM_HandleTypeDef *htim)
{
  if (htim->Instance == TIM6) {
    HAL_IncTick();
  }
}

void Error_Handler(void)
{
  __disable_irq();
  while (1)
  {
  }
}
